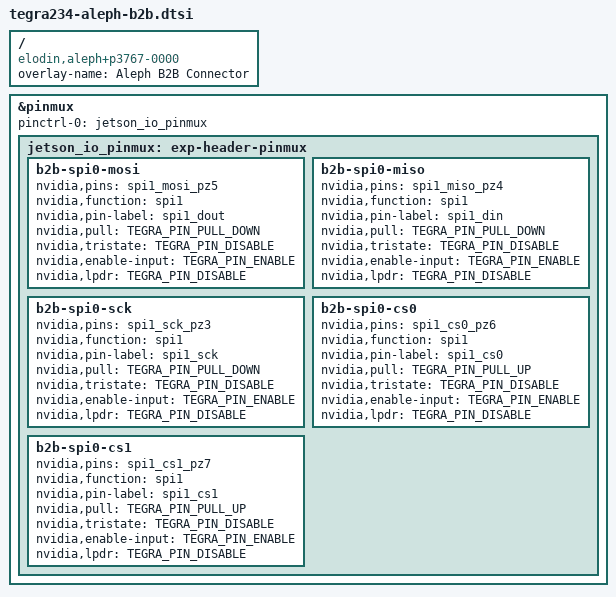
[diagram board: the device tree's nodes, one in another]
/*
 * Copyright (c) 2020-2021, NVIDIA CORPORATION.  All rights reserved.
 *
 * This program is free software; you can redistribute it and/or modify it
 * under the terms and conditions of the GNU General Public License,
 * version 2, as published by the Free Software Foundation.
 *
 * This program is distributed in the hope it will be useful, but WITHOUT
 * ANY WARRANTY; without even the implied warranty of MERCHANTABILITY or
 * FITNESS FOR A PARTICULAR PURPOSE.  See the GNU General Public License for
 * more details.
 *
 * You should have received a copy of the GNU General Public License
 * along with this program.  If not, see <http://www.gnu.org/licenses/>.
 */

/*
 * Device-tree overlay for tegra194-p2888-0004-e3900-0000 40-pin
 * Expansion Header.
 */

/dts-v1/;
/plugin/;

#include <dt-bindings/pinctrl/pinctrl-tegra.h>
#include <dt-common/jetson/tegra194-p2888-0004-e3900-0000.h>

/ {
	overlay-name = "Aleph B2B Connector";
	compatible = "elodin,aleph+p3767-0000";

	fragment@0 {
		target = <&pinmux>;
		__overlay__ {
			pinctrl-names = "default";
			pinctrl-0 = <&jetson_io_pinmux>;
			jetson_io_pinmux: exp-header-pinmux {
				b2b-spi0-mosi {
					nvidia,pins = "spi1_mosi_pz5";
					nvidia,function = "spi1";
					nvidia,pin-label = "spi1_dout";
					nvidia,pull = <TEGRA_PIN_PULL_DOWN>;
					nvidia,tristate = <TEGRA_PIN_DISABLE>;
					nvidia,enable-input = <TEGRA_PIN_ENABLE>;
					nvidia,lpdr = <TEGRA_PIN_DISABLE>;
				};
				b2b-spi0-miso {
					nvidia,pins = "spi1_miso_pz4";
					nvidia,function = "spi1";
					nvidia,pin-label = "spi1_din";
					nvidia,pull = <TEGRA_PIN_PULL_DOWN>;
					nvidia,tristate = <TEGRA_PIN_DISABLE>;
					nvidia,enable-input = <TEGRA_PIN_ENABLE>;
					nvidia,lpdr = <TEGRA_PIN_DISABLE>;
				};
				b2b-spi0-sck {
					nvidia,pins = "spi1_sck_pz3";
					nvidia,function = "spi1";
					nvidia,pin-label = "spi1_sck";
					nvidia,pull = <TEGRA_PIN_PULL_DOWN>;
					nvidia,tristate = <TEGRA_PIN_DISABLE>;
					nvidia,enable-input = <TEGRA_PIN_ENABLE>;
					nvidia,lpdr = <TEGRA_PIN_DISABLE>;
				};
				b2b-spi0-cs0 {
					nvidia,pins = "spi1_cs0_pz6";
					nvidia,function = "spi1";
					nvidia,pin-label = "spi1_cs0";
					nvidia,pull = <TEGRA_PIN_PULL_UP>;
					nvidia,tristate = <TEGRA_PIN_DISABLE>;
					nvidia,enable-input = <TEGRA_PIN_ENABLE>;
					nvidia,lpdr = <TEGRA_PIN_DISABLE>;
				};
				b2b-spi0-cs1 {
					nvidia,pins = "spi1_cs1_pz7";
					nvidia,function = "spi1";
					nvidia,pin-label = "spi1_cs1";
					nvidia,pull = <TEGRA_PIN_PULL_UP>;
					nvidia,tristate = <TEGRA_PIN_DISABLE>;
					nvidia,enable-input = <TEGRA_PIN_ENABLE>;
					nvidia,lpdr = <TEGRA_PIN_DISABLE>;
				};
			};
		};
	};
};
